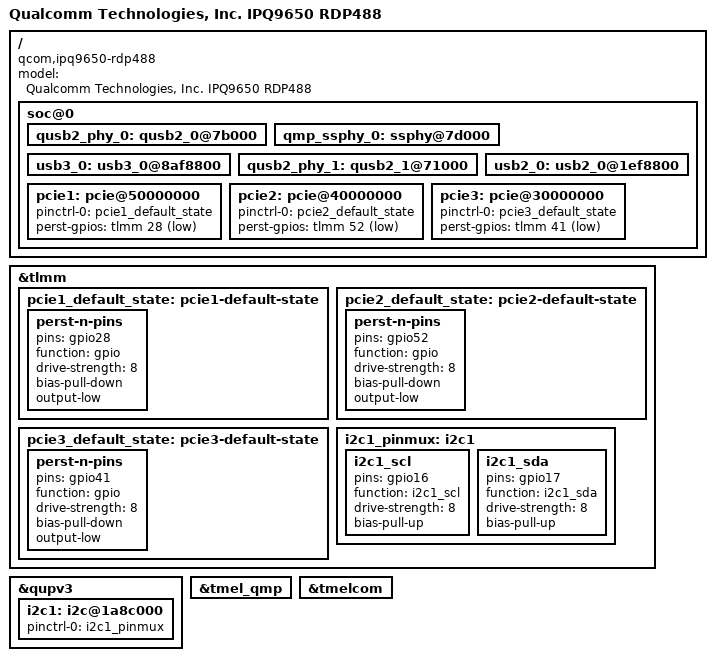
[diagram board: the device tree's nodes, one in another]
// SPDX-License-Identifier: GPL-2.0-only
/*
 * Copyright (c) Qualcomm Technologies, Inc. and/or its subsidiaries.
 */

/dts-v1/;

#include "ipq9650-u-boot.dtsi"

/ {
	model = "Qualcomm Technologies, Inc. IPQ9650 RDP488";
	compatible = "qcom,ipq9650-rdp488", "qcom,ipq9650";

	soc@0 {
		qusb2_phy_0: qusb2_0@7b000 {
			status = "okay";
		};

		qmp_ssphy_0: ssphy@7d000 {
			status = "okay";
		};

		usb3_0: usb3_0@8af8800 {
			status = "okay";
		};

		qusb2_phy_1: qusb2_1@71000 {
			status = "okay";
		};

		usb2_0: usb2_0@1ef8800 {
			status = "okay";
		};

		pcie1: pcie@50000000 {
			pinctrl-0 = <&pcie1_default_state>;
			pinctrl-names = "default";
			perst-gpios = <&tlmm 28 GPIO_ACTIVE_LOW>;
			status = "okay";
		};

		pcie2: pcie@40000000 {
			pinctrl-0 = <&pcie2_default_state>;
			pinctrl-names = "default";
			perst-gpios = <&tlmm 52 GPIO_ACTIVE_LOW>;
			status = "okay";
		};

		pcie3: pcie@30000000 {
			pinctrl-0 = <&pcie3_default_state>;
			pinctrl-names = "default";
			perst-gpios = <&tlmm 41 GPIO_ACTIVE_LOW>;
			status = "okay";
		};
	};
};

&tlmm {
	pcie1_default_state: pcie1-default-state {
		perst-n-pins {
			pins = "gpio28";
			function = "gpio";
			drive-strength = <8>;
			bias-pull-down;
			output-low;
		};
	};

	pcie2_default_state: pcie2-default-state {
		perst-n-pins {
			pins = "gpio52";
			function = "gpio";
			drive-strength = <8>;
			bias-pull-down;
			output-low;
		};
	};

	pcie3_default_state: pcie3-default-state {
		perst-n-pins {
			pins = "gpio41";
			function = "gpio";
			drive-strength = <8>;
			bias-pull-down;
			output-low;
		};
	};

	i2c1_pinmux: i2c1 {
		i2c1_scl {
			pins = "gpio16";
			function = "i2c1_scl";
			drive-strength = <8>;
			bias-pull-up;
		};

		i2c1_sda {
			pins = "gpio17";
			function = "i2c1_sda";
			drive-strength = <8>;
			bias-pull-up;
		};
	};
};

&qupv3 {
	i2c1: i2c@1a8c000 {
		pinctrl-0 = <&i2c1_pinmux>;
		pinctrl-names = "default";
		status = "okay";
	};
};

&tmel_qmp {
	status = "okay";
};

&tmelcom {
	status = "okay";
};
